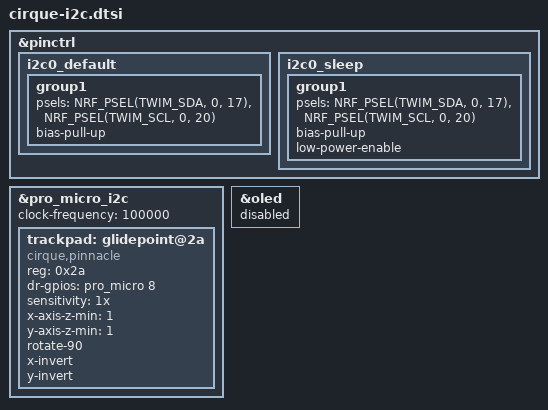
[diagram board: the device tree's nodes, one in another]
#include <dt-bindings/pinctrl/nrf-pinctrl.h>

/* OLED slot on Corne usually has no I2C pull-ups without a screen module.
 * nRF internal pull-ups are weak but enough at 100 kHz. */
&pinctrl {
    i2c0_default: i2c0_default {
        group1 {
            psels = <NRF_PSEL(TWIM_SDA, 0, 17)>,
                    <NRF_PSEL(TWIM_SCL, 0, 20)>;
            bias-pull-up;
        };
    };

    i2c0_sleep: i2c0_sleep {
        group1 {
            psels = <NRF_PSEL(TWIM_SDA, 0, 17)>,
                    <NRF_PSEL(TWIM_SCL, 0, 20)>;
            bias-pull-up;
            low-power-enable;
        };
    };
};

&pro_micro_i2c {
    status = "okay";
    clock-frequency = <100000>;

    trackpad: glidepoint@2a {
        compatible = "cirque,pinnacle";
        reg = <0x2a>;
        status = "okay";
        /* DR wired to Pro Micro pin 8 / silkscreen B4 on the right half. */
        dr-gpios = <&pro_micro 8 (GPIO_ACTIVE_HIGH)>;
        /* 1x = least ADC attenuation = longest detection range. 4x is the opposite. */
        sensitivity = "1x";
        x-axis-z-min = <1>;
        y-axis-z-min = <1>;
        rotate-90;
        x-invert;
        y-invert;
    };
};

&oled {
    status = "disabled";
};
